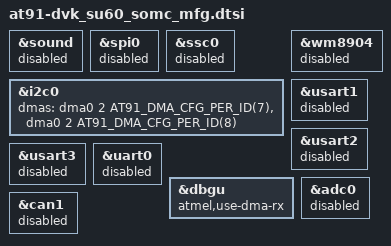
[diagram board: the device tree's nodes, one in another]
// SPDX-License-Identifier: LicenseRef-Ezurio-Clause
/*
 * at91-dvk_su60_somc_mfg.dtsi - Device Tree file for the Manufacturing SOM60 board
 *
 * Copyright (C) 2018 Ezurio
 */

#include "at91-dvk_su60_somc.dtsi"

&sound {
	status = "disabled";
};

&spi0 {
	status = "disabled";
};

&ssc0 {
	status = "disabled";
};

&i2c0 {
	dmas = <&dma0 2 AT91_DMA_CFG_PER_ID(7)>,
	       <&dma0 2 AT91_DMA_CFG_PER_ID(8)>;
};

&wm8904 {
	status = "disabled";
};

&usart1 {
	status = "disabled";
};

&usart2 {
	status = "disabled";
};

&usart3 {
	status = "disabled";
};

&uart0 {
	status = "disabled";
};

&dbgu {
	atmel,use-dma-rx;
};

&adc0 {
	status = "disabled";
};

&can1 {
	status = "disabled";
};
